AUTOSAR XML (schema 00049)
package /Company/Powertrain/Components
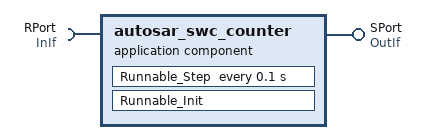
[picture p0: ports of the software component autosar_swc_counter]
  application sw component type autosar_swc_counter
    require port RPort: nonqueued-receiver-com-spec{data-element=InData, alive-timeout=60, init-value=0}, required-interface=InIf
    provide port SPort: nonqueued-sender-com-spec{data-element=OutData, init-value=0}, provided-interface=OutIf
    behavior ASWC_IB: handle-termination-and-restart=NO-SUPPORT
      constant-memorys:
        parameter data prototype INC: category=VALUE, sw-addr-method=VAR, sw-calibration-access=READ-WRITE, type=UInt8_my_qualifier_const, init-value=constant-reference={short-label=INC, constant=INC}
      static-memorys:
        data SM_X: category=VALUE, sw-calibration-access=READ-ONLY, type=uint8
      ar-typed-per-instance-memorys:
        data PIM_sum_out: category=VALUE, sw-calibration-access=READ-ONLY, type=uint8
        data autosar_swc_counter_switch_out: category=VALUE, sw-calibration-access=READ-ONLY, type=uint8
        data SM_equal_to_count: category=VALUE, sw-addr-method=VAR, sw-calibration-access=READ-ONLY, type=boolean
      timing event Event_Step: start-on-event=Runnable_Step, period=0.1
      runnable Runnable_Init: sw-addr-method=CODE
      runnable Runnable_Step: sw-addr-method=CODE
        data-read-access:
          access IN_RPort_InData: accessed-variable=RPort.InData
        data-write-access:
          access OUT_SPort_OutData: accessed-variable=SPort.OutData
        parameter access SCALPRM_K: accessed-parameter=K
      shared-parameters:
        parameter data prototype K: category=VALUE, sw-calibration-access=READ-WRITE, type=uint8, init-value=constant-reference={short-label=K, constant=K}
